# bb_top_model: IP-XACT component
VLNV IcronTechnologies:IcronTechnologies:bb_top_model:1.0

## Parameters
addr_width = 9
bus_width = 32

## Bus interfaces (logical=physical port)
default_map: slave AGNISYS:AGNISYS:APB:1.0, memory map bb_topmap
  pclk=pclk, presetn=presetn, psel=psel, penable=penable, pwrite=pwrite, pprot=pprot, pstrb=pstrb, pwdata=pwdata, paddr=paddr, pready=pready, prdata=prdata, pslverr=pslverr

## Ports
in pclk
in presetn
in psel
in penable
in pwrite
in pprot[2:0]
in pstrb[(bus_width div 8 )-1:0]
in pwdata[bus_width -1:0]
in paddr[addr_width -1:0]
out pready
out prdata[bus_width -1:0]
out pslverr
in bb_top_regssys_config_env_info_in[7:0]
in bb_top_regssys_config_env_info_in_enb
in bb_top_regssys_config_platform_support_in[7:0]
in bb_top_regssys_config_platform_support_in_enb
in bb_top_regssys_config_base_platform_in[3:0]
in bb_top_regssys_config_base_platform_in_enb
in bb_top_regssys_config_image_type_in[1:0]
in bb_top_regssys_config_image_type_in_enb
in bb_top_regssys_config_part_number_in[3:0]
in bb_top_regssys_config_part_number_in_enb
in bb_top_regssys_config_vendor_in[1:0]
in bb_top_regssys_config_vendor_in_enb
in bb_top_regssys_config_technology_in
in bb_top_regssys_config_technology_in_enb
in bb_top_regsfeature_dp_gtp_in
in bb_top_regsfeature_dp_gtp_in_enb
in bb_top_regsfeature_xadc_in
in bb_top_regsfeature_xadc_in_enb
in bb_top_regsfeature_sl_5g_in
in bb_top_regsfeature_sl_5g_in_enb
in bb_top_regsfeature_rxaui_l0_t1_in
in bb_top_regsfeature_rxaui_l0_t1_in_enb
in bb_top_regsfeature_rxaui_l0_t0_in
in bb_top_regsfeature_rxaui_l0_t0_in_enb
out bb_top_regslink_ctrl_enb
out bb_top_regslink_ctrl_sel_r
out bb_top_regsmdio_ctrl_enb
out bb_top_regsmdio_ctrl_master_bus_sel_r
out bb_top_regsmdio_ctrl_master_mdc_tri_r
out bb_top_regsi2c_ctrl_enb
out bb_top_regsi2c_ctrl_master_bus_sel_r
out bb_top_regsi2c_ctrl_master_scl_tri_r
out bb_top_regsuart_ctrl_enb
out bb_top_regsuart_ctrl_ge_uart_sel_r
out bb_top_regssfp_ctrl_enb
out bb_top_regssfp_ctrl_tx_disable_r
out bb_top_regssfp_ctrl_rs1_r
out bb_top_regssfp_ctrl_rs0_r
in bb_top_regssfp_status_rx_los_in
in bb_top_regssfp_status_rx_los_in_enb
in bb_top_regssfp_status_tx_fault_in
in bb_top_regssfp_status_tx_fault_in_enb
in bb_top_regssfp_status_mod_abs_in
in bb_top_regssfp_status_mod_abs_in_enb
out bb_top_regsusb3phy_ctrl_enb
out bb_top_regsusb3phy_ctrl_force_tx_elec_idle_r
out bb_top_regsusb3phy_ctrl_strapping_done_r
out bb_top_regsusb3phy_ctrl_xtal_dis_r
out bb_top_regsusb3phy_ctrl_ssc_dis_r
out bb_top_regsusb3phy_ctrl_power_present_r
out bb_top_regsusb3phy_ctrl_power_present_sel_r
out bb_top_regsusb3phy_ctrl_out_enable_r
out bb_top_regsusb3phy_ctrl_tx_clk_en_r
out bb_top_regsusb3phy_ctrl_rst_b_r
out bb_top_regsge_ctrl_enb
out bb_top_regsge_ctrl_int_n_r
out bb_top_regsge_ctrl_vbus_det_r
out bb_top_regsge_ctrl_clm_tx_clk_en_r
out bb_top_regsge_ctrl_ref_clk_en_r
out bb_top_regsge_ctrl_boot_sel_r
out bb_top_regsge_ctrl_rst_b_r
out bb_top_regsxmii_ctrl_enb
out bb_top_regsxmii_ctrl_txd_tri_r[7:0]
out bb_top_regsxmii_ctrl_tx_er_tri_r
out bb_top_regsxmii_ctrl_tx_en_tri_r
out bb_top_regsxmii_ctrl_gtx_clk_en_r
out bb_top_regsxmii_ctrl_rst_b_r
out bb_top_regsrs232_ctrl_enb
in bb_top_regsrs232_ctrl_invalid_b_in
in bb_top_regsrs232_ctrl_invalid_b_in_enb
out bb_top_regsrs232_ctrl_force_off_b_r
out bb_top_regsrs232_ctrl_en_b_r
out bb_top_regsicap_wdata_enb
out bb_top_regsicap_wdata_val_r[31:0]
out bb_top_regsregicap_wdata_val_wr_pulse
out bb_top_regsregicap_rdata_val_wr_pulse
out bb_top_regsgrm_soft_rst_ctrl_enb
out bb_top_regsgrm_soft_rst_ctrl_cpu_rst_r
out bb_top_regsgrm_soft_rst_ctrl_link_stats_rx_rst_r
out bb_top_regsgrm_soft_rst_ctrl_sl_5g_rx_rst_r
out bb_top_regsgrm_soft_rst_ctrl_sl_5g_tx_rst_r
out bb_top_regsgrm_soft_rst_ctrl_xmii_rx_rst_r
out bb_top_regsgrm_soft_rst_ctrl_xmii_tx_rst_r
out bb_top_regsgrm_soft_rst_ctrl_ge_clm_rx_rst_r
out bb_top_regsgrm_soft_rst_ctrl_ge_clm_tx_rst_r
out bb_top_regsgrm_soft_rst_ctrl_rs232_rst_r
out bb_top_regsgrm_soft_rst_ctrl_ulp_phy_rst_r
out bb_top_regsgrm_soft_rst_ctrl_ulp_core_rst_r
out bb_top_regsgrm_soft_rst_ctrl_upp_rst_r
out bb_top_regsgrm_soft_rst_ctrl_xusb_rst_r
out bb_top_regsgrm_soft_rst_ctrl_tico_d_ctrl_rst_r
out bb_top_regsgrm_soft_rst_ctrl_dp_source_rst_r
out bb_top_regsgrm_soft_rst_ctrl_tico_e_ctrl_rst_r
out bb_top_regsgrm_soft_rst_ctrl_dp_sink_rst_r
out bb_top_regsgrm_soft_rst_ctrl_dp_aux_hpd_rst_r
out bb_top_regsgrm_soft_rst_ctrl_mca_core_rx_rst_r
out bb_top_regsgrm_soft_rst_ctrl_mca_core_tx_rst_r
out bb_top_regsgrm_soft_rst_ctrl_l3_rx_rst_r
out bb_top_regsgrm_soft_rst_ctrl_l3_tx_rst_r
out bb_top_regsgrm_soft_rst_ctrl_dll_rx_rst_r
out bb_top_regsgrm_soft_rst_ctrl_dll_tx_rst_r
out bb_top_regsgrm_soft_rst_ctrl_gpio_ctrl_rst_r
out bb_top_regsgrm_soft_rst_ctrl_spi_flash_ctrl_rst_r
out bb_top_regsgrm_soft_rst_ctrl_mdio_master_rst_r
out bb_top_regsgrm_soft_rst_ctrl_i2c_slave_rst_r
out bb_top_regsgrm_soft_rst_ctrl_i2c_master_rst_r
out bb_top_regsgrm_soft_rst_ctrl_ge_uart_rst_r
out bb_top_regsgrm_soft_rst_ctrl_bb_uart_rst_r
out bb_top_regsgcm_control_enb
out bb_top_regsgcm_control_link_gt_common_pll0reset_r
out bb_top_regsgcm_control_xmii_tx_clk_sel_r
out bb_top_regsgcm_control_ulp_phy_clk_pll_rst_r
out bb_top_regsgcm_freq_det_enb
out bb_top_regsgcm_freq_det_max_count_r[7:0]
out bb_top_regsgcm_freq_det_clk_sel_r[2:0]
out bb_top_regsgcm_freq_det_go_r
out bb_top_regsgcm_freq_det_dp_enb
out bb_top_regsgcm_freq_det_dp_max_count_r[13:0]
out bb_top_regsgcm_freq_det_dp_clk_sel_r
out bb_top_regsgcm_freq_det_dp_go_r
out bb_top_regsgcm_freq_det_dp_auto_enb
out bb_top_regsgcm_freq_det_dp_auto_auto_enable_r
out bb_top_regsgcm_freq_det_dp_auto_comp_ref_clk_faster_r
out bb_top_regsgcm_freq_det_dp_auto_comp_count_max_r[13:0]
out bb_top_regsgcm_freq_det_dp_auto_comp_count_min_r[13:0]
out bb_top_regsdrp_drp_ctrl_enb
out bb_top_regsdrp_drp_ctrl_drp_di_r[15:0]
out bb_top_regsdrp_drp_ctrl_drp_we_r
out bb_top_regsdrp_drp_ctrl_drp_addr_r[8:0]
out bb_top_regsdrp_drp_en_mask_enb
out bb_top_regsdrp_drp_en_mask_xadc_r
out bb_top_regsdrp_drp_en_mask_sl_5g_gt0_r
out bb_top_regsdrp_drp_en_mask_rxaui_gt1_r
out bb_top_regsdrp_drp_en_mask_rxaui_gt0_r
out bb_top_regsdrp_drp_en_mask_link_mmcm_r
out bb_top_regsdrp_drp_en_mask_link_gt_common_r
out bb_top_regsdrp_drp_en_mask_dp_gt_rxoutclk_mmcm_r
out bb_top_regsdrp_drp_en_mask_dp_gt_txoutclk_mmcm_r
out bb_top_regsdrp_drp_en_mask_dp_gt_common_r
out bb_top_regsdrp_drp_en_mask_dp_gt{n}_r (n=0..3)
out bb_top_regsregdrp_drp_en_mask_dp_gt0_wr_pulse
out bb_top_regsdp_gtp_common_pll_ctrl_enb
out bb_top_regsdp_gtp_common_pll_ctrl_pll1refclksel_r[2:0]
out bb_top_regsdp_gtp_common_pll_ctrl_pll0refclksel_r[2:0]
out bb_top_regsdp_gtp_common_pll_ctrl_pll1pd_r
out bb_top_regsdp_gtp_common_pll_ctrl_pll0pd_r
out bb_top_regsdp_gtp_common_loopback_ctrl_enb
out bb_top_regsdp_gtp_common_loopback_ctrl_gt{n}_loopback_r[2:0] (n=0..3)
out bb_top_regsdp_gtp_tx_tx_clk_ctrl_enb
out bb_top_regsdp_gtp_tx_tx_clk_ctrl_gt{n}_txsysclksel_r[1:0] (n=0..3)
out bb_top_regsdp_gtp_tx_tx_rst_ctrl_enb
out bb_top_regsdp_gtp_tx_tx_rst_ctrl_gt{n}_txpcsreset_r (n=0..3)
out bb_top_regsdp_gtp_tx_tx_rst_ctrl_soft_reset_tx_r
out bb_top_regsdp_gtp_tx_tx_diff_ctrl_enb
out bb_top_regsdp_gtp_tx_tx_diff_ctrl_gt{n}_txdiffctrl_r[3:0] (n=0..3)
out bb_top_regsdp_gtp_tx_tx_post_cursor_enb
out bb_top_regsdp_gtp_tx_tx_post_cursor_gt{n}_txpostcursor_r[4:0] (n=0..3)
out bb_top_regsdp_gtp_tx_tx_pre_cursor_enb
out bb_top_regsdp_gtp_tx_tx_pre_cursor_gt{n}_txprecursor_r[4:0] (n=0..3)
out bb_top_regsdp_gtp_tx_tx_prbs_ctrl_enb
out bb_top_regsdp_gtp_tx_tx_prbs_ctrl_gt{n}_txprbsforceerr_r (n=0..3)
out bb_top_regsdp_gtp_tx_tx_prbs_ctrl_gt{n}_txprbssel_r[2:0] (n=0..3)
out bb_top_regsdp_gtp_tx_tx_misc_ctrl_enb
out bb_top_regsdp_gtp_tx_tx_misc_ctrl_gt{n}_txinhibit_r (n=0..3)
out bb_top_regsdp_gtp_tx_tx_misc_ctrl_gt{n}_txpd_r[1:0] (n=0..3)
out bb_top_regsdp_gtp_tx_tx_misc_ctrl_gt{n}_tx8b10ben_r (n=0..3)
out bb_top_regsdp_gtp_tx_tx_misc_ctrl_gt{n}_txpolarity_r (n=0..3)
out bb_top_regsdp_gtp_rx_rx_clk_ctrl_enb
out bb_top_regsdp_gtp_rx_rx_clk_ctrl_gt{n}_rxsysclksel_r[1:0] (n=0..3)
out bb_top_regsdp_gtp_rx_rx_rst_ctrl_enb
out bb_top_regsdp_gtp_rx_rx_rst_ctrl_gt{n}_rxlpmreset_r (n=0..3)
out bb_top_regsdp_gtp_rx_rx_rst_ctrl_gt{n}_eyescanreset_r (n=0..3)
out bb_top_regsdp_gtp_rx_rx_rst_ctrl_gt{n}_rxpmareset_r (n=0..3)
out bb_top_regsdp_gtp_rx_rx_rst_ctrl_gt{n}_rxpcsreset_r (n=0..3)
out bb_top_regsdp_gtp_rx_rx_rst_ctrl_dont_reset_on_data_error_r
out bb_top_regsdp_gtp_rx_rx_rst_ctrl_soft_reset_rx_r
out bb_top_regsdp_gtp_rx_rx_byte_align_ctrl_enb
out bb_top_regsdp_gtp_rx_rx_byte_align_ctrl_gt{n}_rxpcommaalignen_r (n=0..3)
out bb_top_regsdp_gtp_rx_rx_byte_align_ctrl_gt{n}_rxmcommaalignen_r (n=0..3)
out bb_top_regsdp_gtp_rx_rx_prbs_ctrl_enb
out bb_top_regsdp_gtp_rx_rx_prbs_ctrl_gt{n}_rxprbscntreset_r (n=0..3)
out bb_top_regsdp_gtp_rx_rx_prbs_ctrl_gt{n}_rxprbssel_r[2:0] (n=0..3)
out bb_top_regsdp_gtp_rx_rx_eq_ctrl_enb
out bb_top_regsdp_gtp_rx_rx_eq_ctrl_gt{n}_rxlpmlfhold_r (n=0..3)
out bb_top_regsdp_gtp_rx_rx_eq_ctrl_gt{n}_rxlpmhfovrden_r (n=0..3)
out bb_top_regsdp_gtp_rx_rx_eq_ctrl_gt{n}_rxlpmhfhold_r (n=0..3)
out bb_top_regsdp_gtp_rx_rx_misc_ctrl_enb
out bb_top_regsdp_gtp_rx_rx_misc_ctrl_gt_data_valid_en_r
out bb_top_regsdp_gtp_rx_rx_misc_ctrl_gt{n}_rxcdrhold_r (n=0..3)
out bb_top_regsdp_gtp_rx_rx_misc_ctrl_gt{n}_rxpd_r[1:0] (n=0..3)
out bb_top_regsdp_gtp_rx_rx_misc_ctrl_gt{n}_rxpolarity_r (n=0..3)
out bb_top_regsrxaui_control_enb
out bb_top_regsrxaui_control_fix_missing_start_r
out bb_top_regsrxaui_control_type_sel_r[1:0]
out bb_top_regsrxaui_control_reset_r
out bb_top_regsrxaui_gt_rst_ctrl_enb
out bb_top_regsrxaui_gt_rst_ctrl_gtrxreset_r
out bb_top_regsrxaui_gt_rst_ctrl_gt1_rxbufreset_r
out bb_top_regsrxaui_gt_rst_ctrl_gt0_rxbufreset_r
out bb_top_regsrxaui_gt_rst_ctrl_gt1_rxlpmreset_r
out bb_top_regsrxaui_gt_rst_ctrl_gt0_rxlpmreset_r
out bb_top_regsrxaui_gt_rst_ctrl_gt1_rxpcsreset_r
out bb_top_regsrxaui_gt_rst_ctrl_gt0_rxpcsreset_r
out bb_top_regsrxaui_gt_rst_ctrl_gt1_rxpmareset_r
out bb_top_regsrxaui_gt_rst_ctrl_gt0_rxpmareset_r
out bb_top_regsrxaui_gt_rst_ctrl_gt1_txpcsreset_r
out bb_top_regsrxaui_gt_rst_ctrl_gt0_txpcsreset_r
out bb_top_regsrxaui_gt_rst_ctrl_gt1_txpmareset_r
out bb_top_regsrxaui_gt_rst_ctrl_gt0_txpmareset_r
out bb_top_regsrxaui_gt_tx_diff_ctrl_enb
out bb_top_regsrxaui_gt_tx_diff_ctrl_gt1_txdiffctrl_r[3:0]
out bb_top_regsrxaui_gt_tx_diff_ctrl_gt0_txdiffctrl_r[3:0]
out bb_top_regsrxaui_gt_tx_post_cursor_enb
out bb_top_regsrxaui_gt_tx_post_cursor_gt1_txpostcursor_r[4:0]
out bb_top_regsrxaui_gt_tx_post_cursor_gt0_txpostcursor_r[4:0]
out bb_top_regsrxaui_gt_tx_pre_cursor_enb
out bb_top_regsrxaui_gt_tx_pre_cursor_gt1_txprecursor_r[4:0]
out bb_top_regsrxaui_gt_tx_pre_cursor_gt0_txprecursor_r[4:0]
out bb_top_regsrxaui_gt_rx_eq_ctrl_enb
out bb_top_regsrxaui_gt_rx_eq_ctrl_gt1_rxlpmlfovrden_r
out bb_top_regsrxaui_gt_rx_eq_ctrl_gt0_rxlpmlfovrden_r
out bb_top_regsrxaui_gt_rx_eq_ctrl_gt1_rxlpmlfhold_r
out bb_top_regsrxaui_gt_rx_eq_ctrl_gt0_rxlpmlfhold_r
out bb_top_regsrxaui_gt_rx_eq_ctrl_gt1_rxlpmhfovrden_r
out bb_top_regsrxaui_gt_rx_eq_ctrl_gt0_rxlpmhfovrden_r
out bb_top_regsrxaui_gt_rx_eq_ctrl_gt1_rxlpmhfhold_r
out bb_top_regsrxaui_gt_rx_eq_ctrl_gt0_rxlpmhfhold_r
out bb_top_regsrxaui_gt_prbs_ctrl_enb
out bb_top_regsrxaui_gt_prbs_ctrl_gt1_rxprbscntreset_r
out bb_top_regsrxaui_gt_prbs_ctrl_gt1_rxprbssel_r[2:0]
out bb_top_regsrxaui_gt_prbs_ctrl_gt0_rxprbscntreset_r
out bb_top_regsrxaui_gt_prbs_ctrl_gt0_rxprbssel_r[2:0]
out bb_top_regsrxaui_gt_prbs_ctrl_gt1_txprbsforceerr_r
out bb_top_regsrxaui_gt_prbs_ctrl_gt1_txprbssel_r[2:0]
out bb_top_regsrxaui_gt_prbs_ctrl_gt0_txprbsforceerr_r
out bb_top_regsrxaui_gt_prbs_ctrl_gt0_txprbssel_r[2:0]
out bb_top_regsrxaui_gt_misc_ctrl_enb
out bb_top_regsrxaui_gt_misc_ctrl_gt1_rxcdrhold_r
out bb_top_regsrxaui_gt_misc_ctrl_gt0_rxcdrhold_r
out bb_top_regsrxaui_gt_misc_ctrl_gt1_rxrate_r[2:0]
out bb_top_regsrxaui_gt_misc_ctrl_gt0_rxrate_r[2:0]
out bb_top_regsrxaui_gt_misc_ctrl_gt1_rxpolarity_r
out bb_top_regsrxaui_gt_misc_ctrl_gt0_rxpolarity_r
out bb_top_regsrxaui_gt_misc_ctrl_gt1_loopback_r[2:0]
out bb_top_regsrxaui_gt_misc_ctrl_gt0_loopback_r[2:0]
out bb_top_regsrxaui_gt_misc_ctrl_gt1_txpolarity_r
out bb_top_regsrxaui_gt_misc_ctrl_gt0_txpolarity_r
out bb_top_regsrxaui_gt_misc_ctrl_gt1_txinhibit_r
out bb_top_regsrxaui_gt_misc_ctrl_gt0_txinhibit_r
out bb_top_regsrxaui_stats0_rd2clr_config_enb
out bb_top_regsrxaui_stats0_rd2clr_config_missing_start_r
out bb_top_regsrxaui_stats0_rd2clr_config_gt1_not_in_table_r
out bb_top_regsrxaui_stats0_rd2clr_config_gt1_disp_err_r
out bb_top_regsrxaui_stats0_rd2clr_config_gt0_not_in_table_r
out bb_top_regsrxaui_stats0_rd2clr_config_gt0_disp_err_r
out bb_top_regsrxaui_stats0_gt0_disp_err_rd_valid_out
out bb_top_regsrxaui_stats0_gt0_not_in_table_rd_valid_out
out bb_top_regsrxaui_stats0_gt1_disp_err_rd_valid_out
out bb_top_regsrxaui_stats0_gt1_not_in_table_rd_valid_out
out bb_top_regsrxaui_stats0_missing_start_rd_valid_out
out bb_top_regssl_5g_gt_rst_ctrl_enb
out bb_top_regssl_5g_gt_rst_ctrl_rxbufreset_r
out bb_top_regssl_5g_gt_rst_ctrl_rxlpmreset_r
out bb_top_regssl_5g_gt_rst_ctrl_eyescanreset_r
out bb_top_regssl_5g_gt_rst_ctrl_rxpmareset_r
out bb_top_regssl_5g_gt_rst_ctrl_rxpcsreset_r
out bb_top_regssl_5g_gt_rst_ctrl_dont_reset_on_data_error_r
out bb_top_regssl_5g_gt_rst_ctrl_soft_reset_rx_r
out bb_top_regssl_5g_gt_rst_ctrl_txpmareset_r
out bb_top_regssl_5g_gt_rst_ctrl_txpcsreset_r
out bb_top_regssl_5g_gt_rst_ctrl_soft_reset_tx_r
out bb_top_regssl_5g_gt_tx_ctrl_enb
out bb_top_regssl_5g_gt_tx_ctrl_txprbsforceerr_r
out bb_top_regssl_5g_gt_tx_ctrl_txprbssel_r[2:0]
out bb_top_regssl_5g_gt_tx_ctrl_txpostcursor_r[4:0]
out bb_top_regssl_5g_gt_tx_ctrl_txprecursor_r[4:0]
out bb_top_regssl_5g_gt_tx_ctrl_txdiffctrl_r[3:0]
out bb_top_regssl_5g_gt_tx_ctrl_txinhibit_r
out bb_top_regssl_5g_gt_tx_ctrl_txpolarity_r
out bb_top_regssl_5g_gt_tx_ctrl_txpd_r[1:0]
out bb_top_regssl_5g_gt_rx_ctrl_enb
out bb_top_regssl_5g_gt_rx_ctrl_rxprbscntreset_r
out bb_top_regssl_5g_gt_rx_ctrl_rxprbssel_r[2:0]
out bb_top_regssl_5g_gt_rx_ctrl_rxlpmlfhold_r
out bb_top_regssl_5g_gt_rx_ctrl_rxlpmhfovrden_r
out bb_top_regssl_5g_gt_rx_ctrl_rxlpmhfhold_r
out bb_top_regssl_5g_gt_rx_ctrl_rxcdrhold_r
out bb_top_regssl_5g_gt_rx_ctrl_data_valid_en_r
out bb_top_regssl_5g_gt_rx_ctrl_rxpolarity_r
out bb_top_regssl_5g_gt_rx_ctrl_rxpd_r[1:0]
out bb_top_regssl_5g_gt_misc_ctrl_enb
out bb_top_regssl_5g_gt_misc_ctrl_loopback_r[2:0]
out bb_top_regssl_5g_stats0_rd2clr_config_enb
out bb_top_regssl_5g_stats0_rd2clr_config_gt_rxbyterealign_r
out bb_top_regssl_5g_stats0_rd2clr_config_gt_not_in_table_r
out bb_top_regssl_5g_stats0_rd2clr_config_gt_disp_err_r
out bb_top_regssl_5g_stats0_gt_disp_err_rd_valid_out
out bb_top_regssl_5g_stats0_gt_not_in_table_rd_valid_out
out bb_top_regssl_5g_stats0_gt_rxbyterealign_rd_valid_out

## Address spaces and blocks
bb_topmap.bb_top: base 0x000, range 0x200, width 32

## Registers
Registers are 32-bit, read-write, reset 0x0 unless marked. A register's access mark holds for its fields unless they carry their own. Offsets are from the block's base; lines under a group give offsets from that group; [hi:lo] are bit positions; {n}, {i} and the like mark numbered series; 'fields as' and 'values as' point back to an identical list; <NAME> marks a mode.

## bb_topmap.bb_top — BlackBird Global Registers for A7 Core
Base 0x00000000
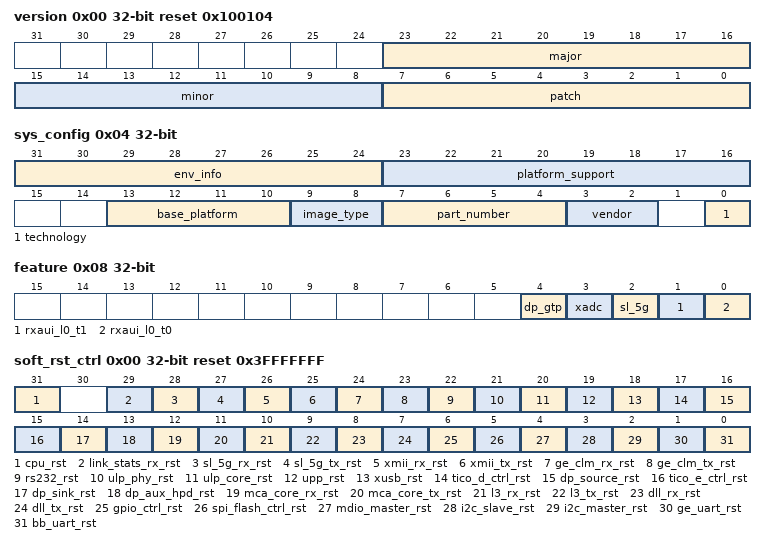
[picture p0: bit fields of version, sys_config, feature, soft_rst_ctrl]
0x00 version ro reset 0x100104
  [23:16] major — Major version
  [15:8] minor — Minor version
  [7:0] patch — Patch version
0x04 sys_config ro — System configuration
  [31:24] env_info — Environment Information - See tech register spreadsheet for details
  [23:16] platform_support — FPGA Platform Support - See tech register spreadsheet for details
  [13:10] base_platform — FPGA Base Platform - See tech register spreadsheet for details
  [9:8] image_type — FPGA Image Type - See tech register spreadsheet for details
  [7:4] part_number — Part Number - See tech register spreadsheet for details
  [3:2] vendor — Vendor Information - See tech register spreadsheet for details
  [0] technology — Technology - See tech register spreadsheet for details
0x08 feature ro — Features present
  [4] dp_gtp — DisplayPort transceivers present
  [3] xadc — XADC present
  [2] sl_5g — Single Lane 5G present
  [1] rxaui_l0_t1 — RXAUI with lane 0 mapped to transceiver 1 present
  [0] rxaui_l0_t0 — RXAUI with lane 0 mapped to transceiver 0 present
0x0C icap group — ICAP register group
  0x00 wdata — Write Data
    [31:0] val — ICAP Write Data
  0x04 rdata — Read Data
    [31:0] val — ICAP Read Data
0x14 grm group — Global Register Module registers group
  0x00 soft_rst_ctrl reset 0x3FFFFFFF — Soft Module Reset Control register
    [31] cpu_rst — CPU Reset (Active-High)
    [29] link_stats_rx_rst — Link Stats RX Reset (Active-High)
    [28] sl_5g_rx_rst — SL 5G RX Reset (Active-High)
    [27] sl_5g_tx_rst — SL 5G TX Reset (Active-High)
    [26] xmii_rx_rst — XMII RX Reset (Active-High)
    [25] xmii_tx_rst — XMII TX Reset (Active-High)
    [24] ge_clm_rx_rst — GE CLM RX Reset (Active-High)
    [23] ge_clm_tx_rst — GE CLM TX Reset (Active-High)
    [22] rs232_rst — RS-232 Reset (Active-High)
    [21] ulp_phy_rst — ULP PHY Reset (Active-High)
    [20] ulp_core_rst — ULP Core Reset (Active-High)
    [19] upp_rst — UPP Reset (Active-High)
    [18] xusb_rst — XUSB Reset (Active-High)
    [17] tico_d_ctrl_rst — TICO Decoder Control Reset (Active-High)
    [16] dp_source_rst — DisplayPort Source Reset (Active-High)
    [15] tico_e_ctrl_rst — TICO Encoder Control Reset (Active-High)
    [14] dp_sink_rst — DisplayPort Sink Reset (Active-High)
    [13] dp_aux_hpd_rst — DisplayPort AUX and HPD Reset (Active-High)
    [12] mca_core_rx_rst — MCA Core RX Reset (Active-High)
    [11] mca_core_tx_rst — MCA Core TX Reset (Active-High)
    [10] l3_rx_rst — Layer 3 RX Reset (Active-High)
    [9] l3_tx_rst — Layer 3 TX Reset (Active-High)
    [8] dll_rx_rst — Data Link Layer RX Reset (Active-High)
    [7] dll_tx_rst — Data Link Layer TX Reset (Active-High)
    [6] gpio_ctrl_rst — GPIO Controller Reset (Active-High)
    [5] spi_flash_ctrl_rst — SPI Flash Controller Reset (Active-High)
    [4] mdio_master_rst — MDIO Master Reset (Active-High)
    [3] i2c_slave_rst — I2C Slave Reset (Active-High)
    [2] i2c_master_rst — I2C Master Reset (Active-High)
    [1] ge_uart_rst — GoldenEars UART Reset (Active-High)
    [0] bb_uart_rst — BlackBird UART Reset (Active-High)
0x18 gcm group — Global Clock Module register group
  0x00 control reset 0x101 — GCM Control register
    [8] link_gt_common_pll0reset — Link GTPE2 COMMON PLL0RESET (Active-High) (See UG482, Table 2-8)
    [4] xmii_tx_clk_sel — XMII TX CLK Select: 0 : GMII Reference Clock 1 : TX_CLK
    [0] ulp_phy_clk_pll_rst — ULP PHY Clock PLL Reset (Active-High)
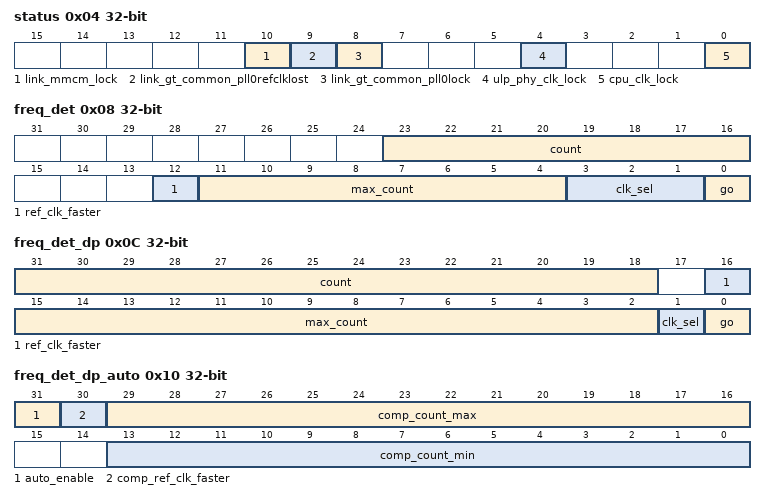
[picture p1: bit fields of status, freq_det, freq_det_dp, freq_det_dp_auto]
  0x04 status ro — GCM Status register
    [10] link_mmcm_lock — Link MMCM (Active-High)
    [9] link_gt_common_pll0refclklost — Link GTPE2 COMMON PLL0REFCLKLOST (Active-High) (See UG482, Table 2-8)
    [8] link_gt_common_pll0lock — Link GTPE2 COMMON PLL0LOCK (Active-High) (See UG482, Table 2-8)
    [4] ulp_phy_clk_lock — ULP PHY Clock PLL Lock (Active-High)
    [0] cpu_clk_lock — CPU Clock MMCM Lock (Active-High)
  0x08 freq_det access per field — Frequency Detect register
    [23:16] count ro — Count value used for frequency calculation: if (ref_clk_faster) freq_min(det_clk) = freq(ref_clk)*((count+2)/(max_count+1)) freq_max(det_clk) = freq(ref_clk)*((count+4)/(max_count-1)) else freq_min(det_clk) = freq(ref_clk)*((max_count+2)/(count+1)) freq_max(det_clk) = freq(ref_clk)*((max_count+4)/(count-1))
    [12] ref_clk_faster ro — This field determines if the reference clock (CPU Clock) is faster than the measured clock (Active-High)
    [11:4] max_count rw — This is the value used for the i_counter_max port of the freq_det module.
    [3:1] clk_sel rw — This field determines which clock is going to be measured: 0 : XMII RX Clock 1 : GE CLM RX Clock 2-7 : Reserved
    [0] go rw — Write a 1 to initiate frequency detection. HW will clear this field upon completion. Once cleared the frequency calculation can be done.
  0x0C freq_det_dp access per field — Frequency Detect DP register
    [31:18] count ro — Count value used for frequency calculation: if (ref_clk_faster) freq_min(det_clk) = freq(ref_clk)*((count+2)/(max_count+1)) freq_max(det_clk) = freq(ref_clk)*((count+4)/(max_count-1)) else freq_min(det_clk) = freq(ref_clk)*((max_count+2)/(count+1)) freq_max(det_clk) = freq(ref_clk)*((max_count+4)/(count-1))
    [16] ref_clk_faster ro — This field determines if the reference clock (CPU Clock) is faster than the measured clock (Active-High)
    [15:2] max_count rw — This is the value used for the i_counter_max port of the freq_det module.
    [1] clk_sel rw — This field determines which clock is going to be measured: 0 : DP GTREFCLK1 (TX Reference Clock) 1 : DP GTREFCLK0 (RX Recovered Clock) 2-7 : Reserved
    [0] go rw — Write a 1 to initiate frequency detection. HW will clear this field upon completion. Once cleared the frequency calculation can be done.
  0x10 freq_det_dp_auto — Frequency Detect DP Auto register
    [31] auto_enable — Automatic Mode Enable: 0 : Manual Mode 1 : Automatic Mode
    [30] comp_ref_clk_faster — In automatic mode the freq_det_dp.ref_clk_faster gets compared with this value
    [29:16] comp_count_max — In automatic mode the freq_det_dp.count gets compared with this value
    [13:0] comp_count_min — In automatic mode the freq_det_dp.count gets compared with this value
0x2C irq group — BlackBird Top Interrupt register group
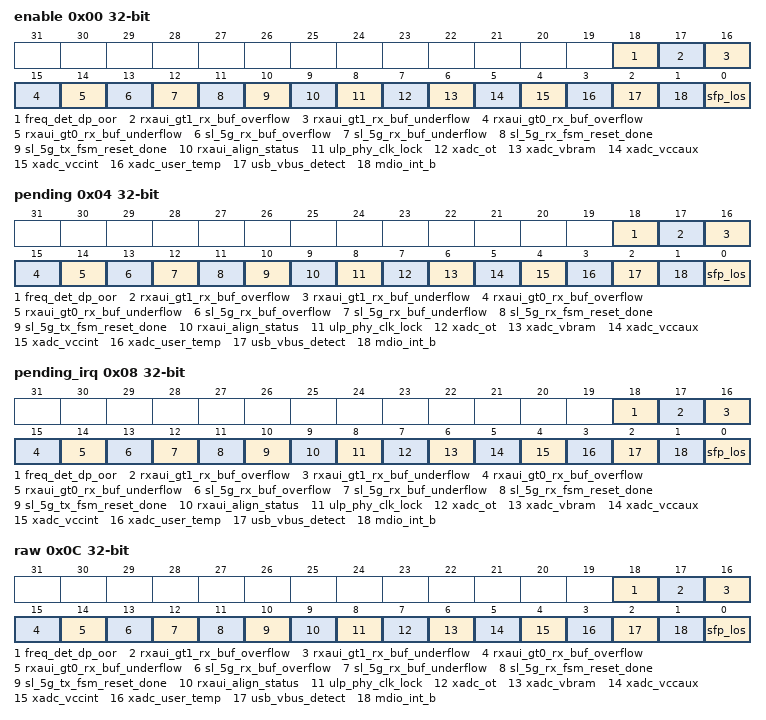
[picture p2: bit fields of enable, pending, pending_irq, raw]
  0x00 enable — Interrupt Enable register - Write 1 to enable, 0 to mask an interrupt
    [18] freq_det_dp_oor — Frequency Detect DP Out Of Range
    [17] rxaui_gt1_rx_buf_overflow — RXAUI GT1 RX Elastic Buffer Overflow (RXBUFSTATUS was 3'b110)
    [16] rxaui_gt1_rx_buf_underflow — RXAUI GT1 RX Elastic Buffer Underflow (RXBUFSTATUS was 3'b101)
    [15] rxaui_gt0_rx_buf_overflow — RXAUI GT0 RX Elastic Buffer Overflow (RXBUFSTATUS was 3'b110)
    [14] rxaui_gt0_rx_buf_underflow — RXAUI GT0 RX Elastic Buffer Underflow (RXBUFSTATUS was 3'b101)
    [13] sl_5g_rx_buf_overflow — SL 5G RX Elastic Buffer Overflow (RXBUFSTATUS was 3'b110)
    [12] sl_5g_rx_buf_underflow — SL 5G RX Elastic Buffer Underflow (RXBUFSTATUS was 3'b101)
    [11] sl_5g_rx_fsm_reset_done — SL 5G RX FSM Reset Done Interrupt
    [10] sl_5g_tx_fsm_reset_done — SL 5G TX FSM Reset Done Interrupt
    [9] rxaui_align_status — RXAUI Align Status Interrupt
    [8] ulp_phy_clk_lock — ULP PHY Clock PLL Lock Interrupt
    [7] xadc_ot — XADC Over-Temperature Alarm Interrupt
    [6] xadc_vbram — XADC VBRAM Sensor Alarm Interrupt
    [5] xadc_vccaux — XADC VCCAUX Sensor Alarm Interrupt
    [4] xadc_vccint — XADC VCCINT Sensor Alarm Interrupt
    [3] xadc_user_temp — XADC Temperature Sensor Alarm Interrupt
    [2] usb_vbus_detect — USB VBUS Detect Interrupt
    [1] mdio_int_b — MDIO Interrupt
    [0] sfp_los — SFP+ Module Connector LOS Interrupt
  0x04 pending — Pending register - This indicates which events are pending, Write 1 to clear
    [18] freq_det_dp_oor write-1-clears — Edge-triggered - Active-High Frequency Detect DP Out Of Range
    [17] rxaui_gt1_rx_buf_overflow write-1-clears — Edge-triggered - Active-High RXAUI GT1 RX Elastic Buffer Overflow
    [16] rxaui_gt1_rx_buf_underflow write-1-clears — Edge-triggered - Active-High RXAUI GT1 RX Elastic Buffer Underflow
    [15] rxaui_gt0_rx_buf_overflow write-1-clears — Edge-triggered - Active-High RXAUI GT0 RX Elastic Buffer Overflow
    [14] rxaui_gt0_rx_buf_underflow write-1-clears — Edge-triggered - Active-High RXAUI GT0 RX Elastic Buffer Underflow
    [13] sl_5g_rx_buf_overflow write-1-clears — Edge-triggered - Active-High SL 5G RX Elastic Buffer Overflow
    [12] sl_5g_rx_buf_underflow write-1-clears — Edge-triggered - Active-High SL 5G RX Elastic Buffer Underflow
    [11] sl_5g_rx_fsm_reset_done write-1-clears — Edge-triggered - Rising and Falling Edge SL 5G RX FSM Reset Done
    [10] sl_5g_tx_fsm_reset_done write-1-clears — Edge-triggered - Active-High SL 5G TX FSM Reset Done
    [9] rxaui_align_status write-1-clears — Edge-triggered - Rising and Falling Edge RXAUI Align Status
    [8] ulp_phy_clk_lock write-1-clears — Edge-triggered - Active High ULP PHY Clock PLL Lock
    [7] xadc_ot write-1-clears — Edge-triggered - Active High XADC Over-Temperature Alarm
    [6] xadc_vbram write-1-clears — Edge-triggered - Active High XADC VBRAM Sensor Alarm
    [5] xadc_vccaux write-1-clears — Edge-triggered - Active High XADC VCCAUX Sensor Alarm
    [4] xadc_vccint write-1-clears — Edge-triggered - Active High XADC VCCINT Sensor Alarm
    [3] xadc_user_temp write-1-clears — Edge-triggered - Active High XADC Temperature Sensor Alarm
    [2] usb_vbus_detect write-1-clears — Edge-triggered - Rising and Falling Edge USB VBUS Detect change
    [1] mdio_int_b write-1-clears — Level-triggered - Active-Low MDIO Interrupt
    [0] sfp_los write-1-clears — Edge-triggered - Rising and Falling Edge SFP+ Module Connector LOS change
  0x08 pending_irq ro — Interrupt Pending register - This indicates which pending events are enabled to cause an interrupt
    [18] freq_det_dp_oor — Edge-triggered - Active-High Frequency Detect DP Out Of Range
    [17] rxaui_gt1_rx_buf_overflow — Edge-triggered - Active-High RXAUI GT1 RX Elastic Buffer Overflow
    [16] rxaui_gt1_rx_buf_underflow — Edge-triggered - Active-High RXAUI GT1 RX Elastic Buffer Underflow
    [15] rxaui_gt0_rx_buf_overflow — Edge-triggered - Active-High RXAUI GT0 RX Elastic Buffer Overflow
    [14] rxaui_gt0_rx_buf_underflow — Edge-triggered - Active-High RXAUI GT0 RX Elastic Buffer Underflow
    [13] sl_5g_rx_buf_overflow — Edge-triggered - Active-High SL 5G RX Elastic Buffer Overflow
    [12] sl_5g_rx_buf_underflow — Edge-triggered - Active-High SL 5G RX Elastic Buffer Underflow
    [11] sl_5g_rx_fsm_reset_done — Edge-triggered - Rising and Falling Edge SL 5G RX FSM Reset Done
    [10] sl_5g_tx_fsm_reset_done — Edge-triggered - Active-High SL 5G TX FSM Reset Done
    [9] rxaui_align_status — Edge-triggered - Rising and Falling Edge RXAUI Align Status
    [8] ulp_phy_clk_lock — Edge-triggered - Active High ULP PHY Clock PLL Lock
    [7] xadc_ot — Edge-triggered - Active High XADC Over-Temperature Alarm
    [6] xadc_vbram — Edge-triggered - Active High XADC VBRAM Sensor Alarm
    [5] xadc_vccaux — Edge-triggered - Active High XADC VCCAUX Sensor Alarm
    [4] xadc_vccint — Edge-triggered - Active High XADC VCCINT Sensor Alarm
    [3] xadc_user_temp — Edge-triggered - Active High XADC Temperature Sensor Alarm
    [2] usb_vbus_detect — Edge-triggered - Rising and Falling Edge USB VBUS Detect change
    [1] mdio_int_b — Level-triggered - Active-Low MDIO Interrupt
    [0] sfp_los — Edge-triggered - Rising and Falling Edge SFP+ Module Connector LOS change
  0x0C raw ro — This register contains the registered state of interrupt signals
    [18] freq_det_dp_oor — Current state of the Frequency Detect DP Out Of Range (Active-High)
    [17] rxaui_gt1_rx_buf_overflow — Current state of the RXAUI GT1 RX Elastic Buffer Overflow (Active-High)
    [16] rxaui_gt1_rx_buf_underflow — Current state of the RXAUI GT1 RX Elastic Buffer Underflow (Active-High)
    [15] rxaui_gt0_rx_buf_overflow — Current state of the RXAUI GT0 RX Elastic Buffer Overflow (Active-High)
    [14] rxaui_gt0_rx_buf_underflow — Current state of the RXAUI GT0 RX Elastic Buffer Underflow (Active-High)
    [13] sl_5g_rx_buf_overflow — Current state of the SL 5G RX Elastic Buffer Overflow (Active-High)
    [12] sl_5g_rx_buf_underflow — Current state of the SL 5G RX Elastic Buffer Underflow (Active-High)
    [11] sl_5g_rx_fsm_reset_done — Current state of the SL 5G RX FSM Reset Done (Active-High)
    [10] sl_5g_tx_fsm_reset_done — Current state of the SL 5G TX FSM Reset Done (Active-High)
    [9] rxaui_align_status — Current state of the RXAUI Align Status (Active-High)
    [8] ulp_phy_clk_lock — Current state of the ULP PHY Clock PLL Lock (Active-High)
    [7] xadc_ot — Current state of the XADC Over-Temperature Alarm (Active-High)
    [6] xadc_vbram — Current state of the XADC VBRAM Sensor Alarm (Active-High)
    [5] xadc_vccaux — Current state of the XADC VCCAUX Sensor Alarm (Active-High)
    [4] xadc_vccint — Current state of the XADC VCCINT Sensor Alarm (Active-High)
    [3] xadc_user_temp — Current state of the XADC Temperature Sensor Alarm (Active-High)
    [2] usb_vbus_detect — Current state of the USB VBUS Detect (Active-High)
    [1] mdio_int_b — Current state of the MDIO Interrupt (Active-Low)
    [0] sfp_los — Current state of the SFP+ Module Connector LOS (Active-High)
0x3C link_ctrl — Link Control
  [0] sel — Link Select 0 : RXAUI 1 : SL 5G
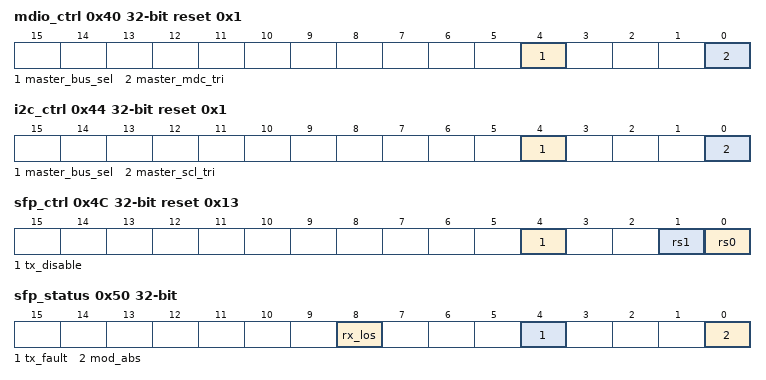
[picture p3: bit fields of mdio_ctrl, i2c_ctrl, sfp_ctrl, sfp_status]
0x40 mdio_ctrl reset 0x1 — MDIO Control
  [4] master_bus_sel — MDIO Master Bus Select 0 : Mother board (connector) 1 : RXAUI Core (internal)
  [0] master_mdc_tri — MDIO Master Clock (MDC) Tri-State (Active-High)
0x44 i2c_ctrl reset 0x1 — I2C Control
  [4] master_bus_sel — I2C Master Bus Select 0 : Core board (local) 1 : Mother board (connector)
  [0] master_scl_tri — I2C Master Clock (SCL) Tri-State (Active-High)
0x48 uart_ctrl — UART Control
  [0] ge_uart_sel — GE UART Select 0 : Mother board (connector) 1 : GE UART (internal)
0x4C sfp_ctrl reset 0x13 — SFP Control
  [4] tx_disable — Transmitter Disable 0 : Module transmitter enabled 1 : Module transmitter disabled
  [1] rs1 — Rate Select TX 0 : TX signalling rate less than or equal to 4.25 GBd 1 : TX signalling rate greater than 4.25 GBd
  [0] rs0 — Rate Select RX 0 : RX signalling rate less than or equal to 4.25 GBd 1 : RX signalling rate greater than 4.25 GBd
0x50 sfp_status ro
  [8] rx_los — RX LOS (Active-High) - Indicates an optical signal level below that specified in the relevant standard
  [4] tx_fault — TX Fault (Active-High) - Module transmitter detected a fault
  [0] mod_abs — Module Absent (Active-High) - SFP+ module is physically absent
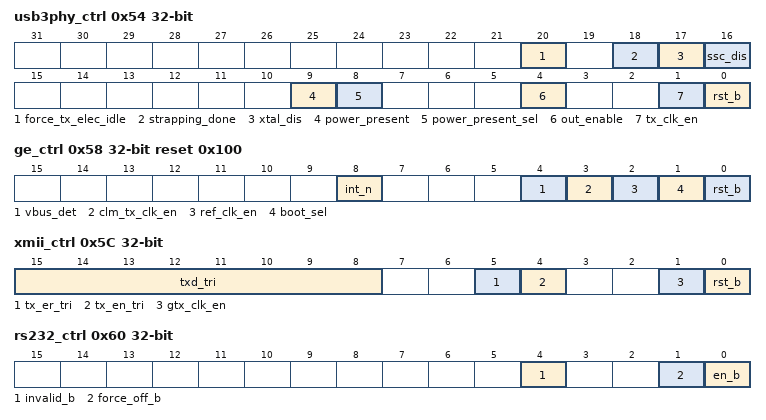
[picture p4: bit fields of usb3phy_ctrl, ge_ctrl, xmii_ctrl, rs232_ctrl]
0x54 usb3phy_ctrl — USB3PHY Control
  [20] force_tx_elec_idle — When this is set to 1, it forces the FPGA PIPE TX to Electrical Idle. Only used for hardware test to isolate the PIPE RX path from cross talk of TX path.
  [18] strapping_done — This register is used for dynamic strapping to select the proper path for strap options: xtal_dis and ssc_dis. Assert high when strapping is completed (This should be asserted after PHY is out of reset using rst_b). See also "out_enable"
  [17] xtal_dis — Strap Option - Selects an input clock source 0 : Crystal input 1 : Clock input
  [16] ssc_dis — Strap Option - Spread spectrum clocking disable 0 : SSC enable 1 : SSC disable
  [9] power_present — Power Present to the ULP
  [8] power_present_sel — Power Present Select for the ULP: 0 : VBUS Detect 1 : usb3phy_ctrl.power_present register field
  [4] out_enable — Assert high to enable PHY outputs. Assert after PHY is out of reset and when dynamic strapping is complete. See rst_b and strapping_done.
  [1] tx_clk_en — Forwarded TX Clock Enable (Active-High)
  [0] rst_b — Reset (Active-Low)
0x58 ge_ctrl reset 0x100 — GE Control
  [8] int_n — Interrupt (Active-Low)
  [4] vbus_det — VBUS Detect (Active-High)
  [3] clm_tx_clk_en — Forwarded CLM TX Clock Enable (Active-High)
  [2] ref_clk_en — 125 MHz Reference Clock Enable (Active-High)
  [1] boot_sel — Boot Select 0 : Program Mode 1 : Boot from Flash
  [0] rst_b — Reset (Active-Low)
0x5C xmii_ctrl — XMII Control
  [15:8] txd_tri — TXD Tri-State (Active-High)
  [5] tx_er_tri — TX ER Tri-State (Active-High)
  [4] tx_en_tri — TX EN Tri-State (Active-High)
  [1] gtx_clk_en — Forwarded GTX Clock Enable (Active-High)
  [0] rst_b — Reset (Active-Low)
0x60 rs232_ctrl access per field — RS232 Control
  [4] invalid_b ro — Receiver Input (RIN) Invalid (Active-Low)
  [1] force_off_b rw — Automatic Power-Down (Active-Low)
  [0] en_b rw — Receiver Output (ROUT) Enable (Active-Low)
0x100 drp group — DRP register group
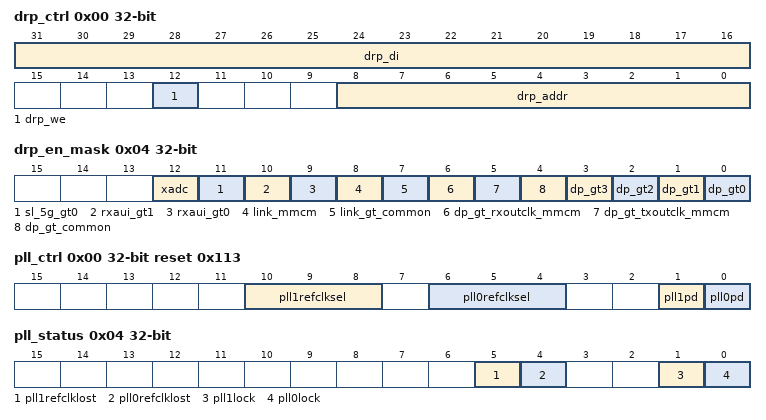
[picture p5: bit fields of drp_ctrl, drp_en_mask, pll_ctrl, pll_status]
  0x00 drp_ctrl — DRP Control and Write Data. Note: make sure this register is setup before writing to the drp_en_mask register
    [31:16] drp_di — DRP Write Data
    [12] drp_we — DRP Write Enable
    [8:0] drp_addr — DRP Address
  0x04 drp_en_mask — DRP Enable Mask for each DRP bus. - A write to this register initiates a transaction to each enabled DRP bus. - A field gets cleared when its respective DRP bus asserts DRPRDY. Note: before attempting a new transaction, make sure no DRP bus is busy (all fields should be cleared) Note: always enable exactly 1 DRP bus for read transfers, write transfers can have any combination of DRP buses enabled Note: following a read transaction make sure the DRP bus has asserted DRPRDY (its DRP Enable Mask field should be cleared) before reading the drp_read_data register.
    [12] xadc — DRP Enable Mask for XADC
    [11] sl_5g_gt0 — DRP Enable Mask for SL 5G GT0
    [10] rxaui_gt1 — DRP Enable Mask for RXAUI GT1
    [9] rxaui_gt0 — DRP Enable Mask for RXAUI GT0
    [8] link_mmcm — DRP Enable Mask for Link MMCM
    [7] link_gt_common — DRP Enable Mask for Link GT COMMON
    [6] dp_gt_rxoutclk_mmcm — DRP Enable Mask for DP GT RXOUTCLK MMCM
    [5] dp_gt_txoutclk_mmcm — DRP Enable Mask for DP GT TXOUTCLK MMCM
    [4] dp_gt_common — DRP Enable Mask for DP GT COMMON
    [n] dp_gt{n} (n=0..3) — DRP Enable Mask for DP GT{n}
  0x08 drp_read_data ro — DRP Read Data Note: make sure the DRP bus has asserted DRPRDY (its DRP Enable Mask field in the drp_en_mask register should be cleared) before reading this register
    [15:0] drp_do — DRP Read Data
0x10C dp_gtp_common group — DisplayPort GTP common register group
  0x00 pll_ctrl reset 0x113 — PLL Control
    [10:8] pll1refclksel — PLL1REFCLKSEL (See UG482, Table 2-8)
    [6:4] pll0refclksel — PLL0REFCLKSEL (See UG482, Table 2-8)
    [1] pll1pd — PLL1PD (Active-High) (See UG482, Table 2-8)
    [0] pll0pd — PLL0PD (Active-High) (See UG482, Table 2-8)
  0x04 pll_status ro
    [5] pll1refclklost — PLL1REFCLKLOST (Active-High) (See UG482, Table 2-8)
    [4] pll0refclklost — PLL0REFCLKLOST (Active-High) (See UG482, Table 2-8)
    [1] pll1lock — PLL1LOCK (Active-High) (See UG482, Table 2-8)
    [0] pll0lock — PLL0LOCK (Active-High) (See UG482, Table 2-8)
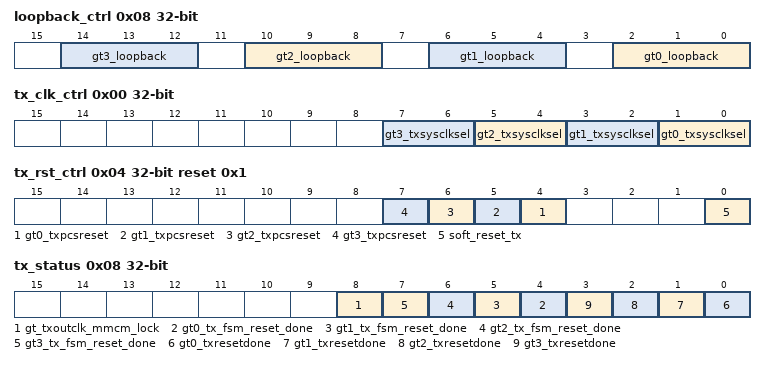
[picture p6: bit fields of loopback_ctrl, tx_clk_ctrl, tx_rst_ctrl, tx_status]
  0x08 loopback_ctrl — Loopback Control
    [4n+2:4n] gt{n}_loopback (n=0..3) — GT{n} LOOPBACK (See UG482, Table 2-27)
0x118 dp_gtp_tx group — DisplayPort GTP TX register group
  0x00 tx_clk_ctrl — GTP TX Clock Control
    [2n+1:2n] gt{n}_txsysclksel (n=0..3) — GT{n} TXSYSCLKSEL (See UG482, Table 2-6)
  0x04 tx_rst_ctrl reset 0x1 — GTP TX Reset Control
    [n+4] gt{n}_txpcsreset (n=0..3) — GT{n} TXPCSRESET (Active-High) (See UG482, Table 2-14)
    [0] soft_reset_tx — Soft Reset of TX path of all DP GTPs (Active-High) 1'b0 - All GTP TX Reset FSMs are out of reset 1'b1 - All GTP TX Reset FSMs are in reset Note: To reset write a 1 followed by a 0
  0x08 tx_status ro — GTP TX Status
    [8] gt_txoutclk_mmcm_lock — GT TXOUTCLK MMCM Lock (Active-High)
    [n+4] gt{n}_tx_fsm_reset_done (n=0..3) — GT{n} TX FSM Reset Done (Active-High)
    [n] gt{n}_txresetdone (n=0..3) — GT{n} TXRESETDONE (Active-High) (See UG482, Table 2-14)
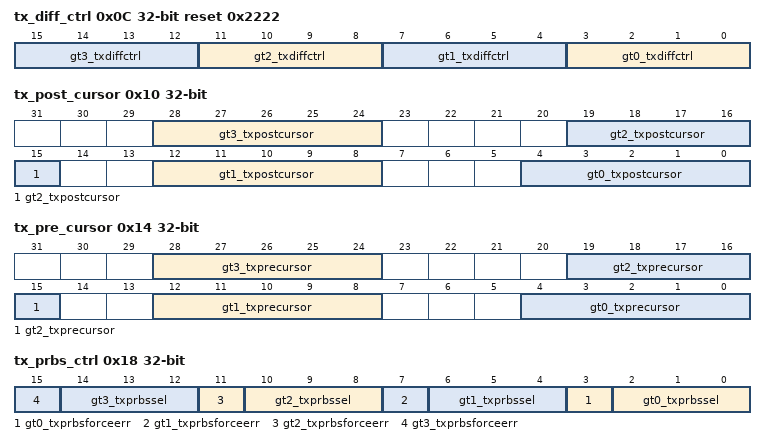
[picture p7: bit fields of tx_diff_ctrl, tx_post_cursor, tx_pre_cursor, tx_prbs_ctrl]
  0x0C tx_diff_ctrl reset 0x2222 — GTP TX Voltage Swing
    [4n+3:4n] gt{n}_txdiffctrl (n=0..3) — GT{n} TXDIFFCTRL (See UG482, Table 3-28)
  0x10 tx_post_cursor — GTP TX Pre-emphasis (Post-Cursor1)
    [28:24] gt3_txpostcursor — GT3 TXPOSTCURSOR (See UG482, Table 3-28)
    [19:15] gt2_txpostcursor — GT2 TXPOSTCURSOR (See UG482, Table 3-28)
    [12:8] gt1_txpostcursor — GT1 TXPOSTCURSOR (See UG482, Table 3-28)
    [4:0] gt0_txpostcursor — GT0 TXPOSTCURSOR (See UG482, Table 3-28)
  0x14 tx_pre_cursor — GTP TX Pre-emphasis (Pre-Cursor)
    [28:24] gt3_txprecursor — GT3 TXPRECURSOR (See UG482, Table 3-28)
    [19:15] gt2_txprecursor — GT2 TXPRECURSOR (See UG482, Table 3-28)
    [12:8] gt1_txprecursor — GT1 TXPRECURSOR (See UG482, Table 3-28)
    [4:0] gt0_txprecursor — GT0 TXPRECURSOR (See UG482, Table 3-28)
  0x18 tx_prbs_ctrl — GTP TX Pattern Generator Control
    [4n+3] gt{n}_txprbsforceerr (n=0..3) — GT{n} TXPRBSFORCEERR (Active-High) (See UG482, Table 3-20)
    [4n+2:4n] gt{n}_txprbssel (n=0..3) — GT{n} TXPRBSSEL (See UG482, Table 3-20)
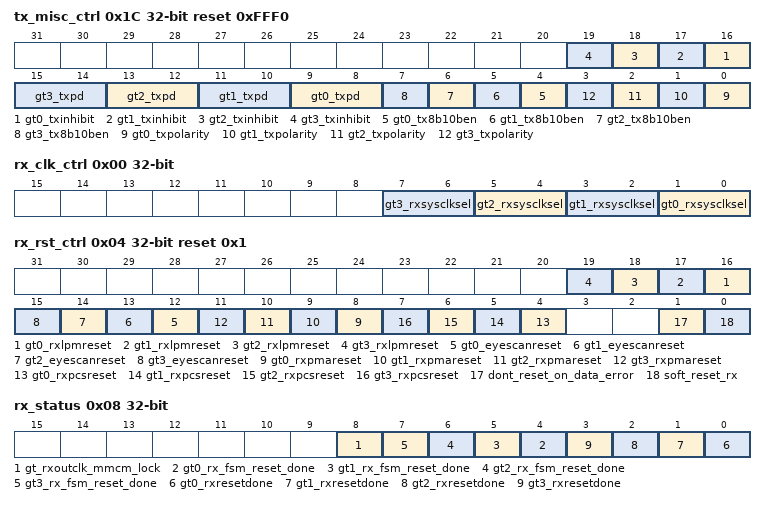
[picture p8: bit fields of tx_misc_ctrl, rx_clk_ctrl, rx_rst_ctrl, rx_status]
  0x1C tx_misc_ctrl reset 0xFFF0 — GTP TX Miscellaneous Control
    [n+16] gt{n}_txinhibit (n=0..3) — GT{n} TXINHIBIT (Active-High) (See UG482, Table 3-28)
    [2n+9:2n+8] gt{n}_txpd (n=0..3) — GT{n} TXPD (See UG482, Table 3-30)
    [n+4] gt{n}_tx8b10ben (n=0..3) — GT{n} TX8B10BEN (Active-High) (See UG482, Table 3-7)
    [n] gt{n}_txpolarity (n=0..3) — GT{n} TXPOLARITY (See UG482, Table 3-22)
0x138 dp_gtp_rx group — DisplayPort GTP RX register group
  0x00 rx_clk_ctrl — GTP TX Clock Control
    [2n+1:2n] gt{n}_rxsysclksel (n=0..3) — GT{n} RXSYSCLKSEL (See UG482, Table 2-6)
  0x04 rx_rst_ctrl reset 0x1 — GTP RX Reset Control
    [n+16] gt{n}_rxlpmreset (n=0..3) — GT{n} RXLPMRESET (Active-High) (See UG482, Table 4-18)
    [n+12] gt{n}_eyescanreset (n=0..3) — GT{n} EYESCANRESET (Active-High) (See UG482, Table 2-18)
    [n+8] gt{n}_rxpmareset (n=0..3) — GT{n} RXPMARESET (Active-High) (See UG482, Table 2-18)
    [n+4] gt{n}_rxpcsreset (n=0..3) — GT{n} RXPCSRESET (Active-High) (See UG482, Table 2-18)
    [1] dont_reset_on_data_error — Do not automatically reset the RX_STARTUP_FSM of a GTP when its DATA_VALID input de-asserts.
    [0] soft_reset_rx — Soft Reset of RX path of all DP GTPs (Active-High) 1'b0 - All GTP RX Reset FSMs are out of reset 1'b1 - All GTP RX Reset FSMs are in reset Note: To reset write a 1 followed by a 0
  0x08 rx_status ro — GTP RX Status
    [8] gt_rxoutclk_mmcm_lock — GT RXOUTCLK MMCM Lock (Active-High)
    [n+4] gt{n}_rx_fsm_reset_done (n=0..3) — GT{n} RX FSM Reset Done (Active-High)
    [n] gt{n}_rxresetdone (n=0..3) — GT{n} RXRESETDONE (Active-High) (See UG482, Table 2-18)
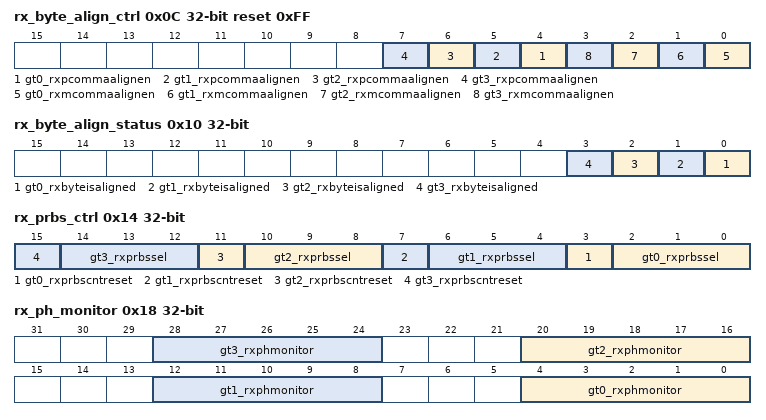
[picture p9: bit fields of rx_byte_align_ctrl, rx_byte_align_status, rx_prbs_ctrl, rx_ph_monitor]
  0x0C rx_byte_align_ctrl reset 0xFF — GTP RX Byte Alignment Control
    [n+4] gt{n}_rxpcommaalignen (n=0..3) — GT{n} RXPCOMMAALIGNEN (See UG482, Table 4-25)
    [n] gt{n}_rxmcommaalignen (n=0..3) — GT{n} RXMCOMMAALIGNEN (See UG482, Table 4-25)
  0x10 rx_byte_align_status ro — GTP RX Byte Alignment Status
    [n] gt{n}_rxbyteisaligned (n=0..3) — GT{n} RXBYTEISALIGNED (See UG482, Table 4-25)
  0x14 rx_prbs_ctrl — GTP RX Pattern Receiver Control
    [4n+3] gt{n}_rxprbscntreset (n=0..3) — GT{n} RXPRBSCNTRESET (Active-High) (See UG482, Table 4-23)
    [4n+2:4n] gt{n}_rxprbssel (n=0..3) — GT{n} RXPRBSSEL (See UG482, Table 4-23)
  0x18 rx_ph_monitor ro — GTP RX Phase Alignment Monitor
    [8n+4:8n] gt{n}_rxphmonitor (n=0..3) — GT{n} RXPHMONITOR (See UG482, Table 4-29)
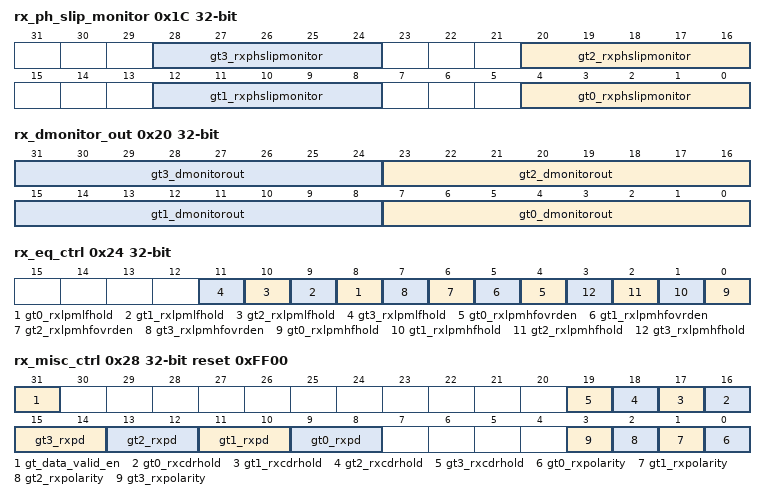
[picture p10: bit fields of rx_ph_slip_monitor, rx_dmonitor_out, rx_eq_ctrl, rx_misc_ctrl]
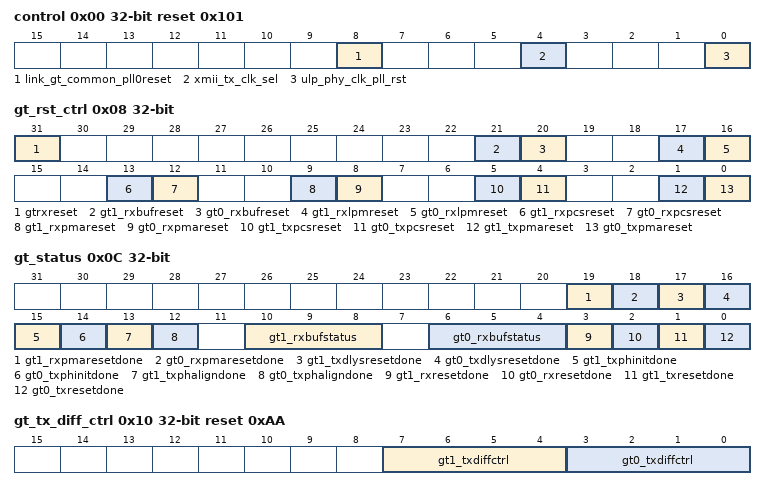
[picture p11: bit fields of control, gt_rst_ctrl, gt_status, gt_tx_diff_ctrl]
  0x1C rx_ph_slip_monitor ro — GTP RX Phase Alignment Slip Monitor
    [8n+4:8n] gt{n}_rxphslipmonitor (n=0..3) — GT{n} RXPHSLIPMONITOR (See UG482, Table 4-29)
  0x20 rx_dmonitor_out ro — GTP RX Digital Monitor Out
    [8n+7:8n] gt{n}_dmonitorout (n=0..3) — GT{n} DMONITOROUT[7:0] (See UG482, Table 2-31)
  0x24 rx_eq_ctrl — GTP RX Equalizer Control
    [n+8] gt{n}_rxlpmlfhold (n=0..3) — GT{n} RXLPMLFHOLD (See UG482, Table 4-9)
    [n+4] gt{n}_rxlpmhfovrden (n=0..3) — GT{n} RXLPMHFOVRDEN (See UG482, Table 4-9)
    [n] gt{n}_rxlpmhfhold (n=0..3) — GT{n} RXLPMHFHOLD (See UG482, Table 4-9)
  0x28 rx_misc_ctrl reset 0xFF00 — GTP RX Miscellaneous Control
    [31] gt_data_valid_en — DATA_VALID input to the GT RX_STARTUP_FSM is: 1'b0 : always 1 1'b1 : hardware defined (generally the NOT of the OR of all 8B/10B decode errors)
    [n+16] gt{n}_rxcdrhold (n=0..3) — GT{n} RXCDRHOLD (See UG482, Table 4-11)
    [2n+9:2n+8] gt{n}_rxpd (n=0..3) — GT{n} RXPD (See UG482, Table 3-30)
    [n] gt{n}_rxpolarity (n=0..3) — GT{n} RXPOLARITY (See UG482, Table 4-22)
0x164 rxaui group — RXAUI register group
  0x00 control reset 0x1
    [8] fix_missing_start — Replace the XGMII Idle with an XGMII Start control character when it is detected missing (see stats0.missing_start)
    [5:4] type_sel — Type Select (See PG083, Table 3-3)
    [0] reset — Asynchronous reset (Active-High)
  0x04 status ro
    [5:0] debug — Debug Port (See PG083, Table 2-18) [0] : TX Phase Align Complete [4:1] : Sync Status [5]: Align Status
  0x08 gt_rst_ctrl — GTP Reset Control register
    [31] gtrxreset — GT0 and GT1 GTRXRESET (Active-High) (See UG482, Table 2-18)
    [21] gt1_rxbufreset — GT1 RXBUFRESET (Active-High) (See UG482, Table 2-18)
    [20] gt0_rxbufreset — GT0 RXBUFRESET (Active-High) (See UG482, Table 2-18)
    [17] gt1_rxlpmreset — GT1 RXLPMRESET (Active-High) (See UG482, Table 2-18)
    [16] gt0_rxlpmreset — GT0 RXLPMRESET (Active-High) (See UG482, Table 2-18)
    [13] gt1_rxpcsreset — GT1 RXPCSRESET (Active-High) (See UG482, Table 2-18)
    [12] gt0_rxpcsreset — GT0 RXPCSRESET (Active-High) (See UG482, Table 2-18)
    [9] gt1_rxpmareset — GT1 RXPMARESET (Active-High) (See UG482, Table 2-18)
    [8] gt0_rxpmareset — GT0 RXPMARESET (Active-High) (See UG482, Table 2-18)
    [5] gt1_txpcsreset — GT1 TXPCSRESET (Active-High) (See UG482, Table 2-14)
    [4] gt0_txpcsreset — GT0 TXPCSRESET (Active-High) (See UG482, Table 2-14)
    [1] gt1_txpmareset — GT1 TXPMARESET (Active-High) (See UG482, Table 2-14)
    [0] gt0_txpmareset — GT0 TXPMARESET (Active-High) (See UG482, Table 2-14)
  0x0C gt_status ro — GTP Status register
    [19] gt1_rxpmaresetdone — GT1 RXPMARESETDONE (Active-High) (See UG482, Table 2-18)
    [18] gt0_rxpmaresetdone — GT0 RXPMARESETDONE (Active-High) (See UG482, Table 2-18)
    [17] gt1_txdlysresetdone — GT1 TXDLYSRESETDONE (Active-High) (See UG482, Table 3-15)
    [16] gt0_txdlysresetdone — GT0 TXDLYSRESETDONE (Active-High) (See UG482, Table 3-15)
    [15] gt1_txphinitdone — GT1 TXPHINITDONE (Active-High) (See UG482, Table 3-15)
    [14] gt0_txphinitdone — GT0 TXPHINITDONE (Active-High) (See UG482, Table 3-15)
    [13] gt1_txphaligndone — GT1 TXPHALIGNDONE (Active-High) (See UG482, Table 3-15)
    [12] gt0_txphaligndone — GT0 TXPHALIGNDONE (Active-High) (See UG482, Table 3-15)
    [10:8] gt1_rxbufstatus — GT1 RXBUFSTATUS (See UG482, Table 4-33)
    [6:4] gt0_rxbufstatus — GT0 RXBUFSTATUS (See UG482, Table 4-33)
    [3] gt1_rxresetdone — GT1 RXRESETDONE (Active-High) (See UG482, Table 2-18)
    [2] gt0_rxresetdone — GT0 RXRESETDONE (Active-High) (See UG482, Table 2-18)
    [1] gt1_txresetdone — GT1 TXRESETDONE (Active-High) (See UG482, Table 2-14)
    [0] gt0_txresetdone — GT0 TXRESETDONE (Active-High) (See UG482, Table 2-14)
  0x10 gt_tx_diff_ctrl reset 0xAA — GTP TX Voltage Swing
    [7:4] gt1_txdiffctrl — GT1 TXDIFFCTRL (See UG482, Table 3-28)
    [3:0] gt0_txdiffctrl — GT0 TXDIFFCTRL (See UG482, Table 3-28)
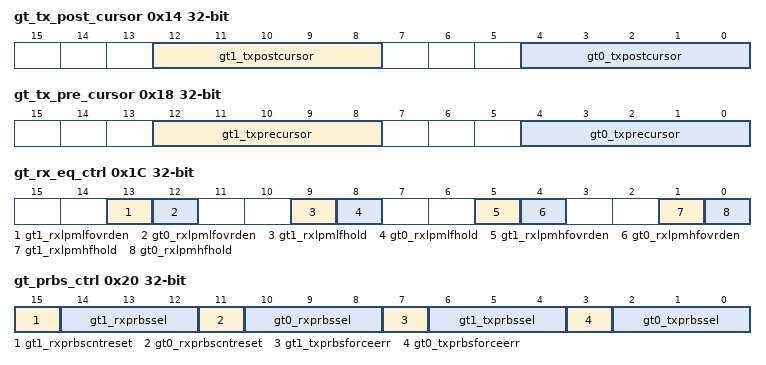
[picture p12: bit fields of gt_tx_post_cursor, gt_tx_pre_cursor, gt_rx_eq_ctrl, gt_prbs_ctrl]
  0x14 gt_tx_post_cursor — GTP TX Pre-emphasis (Post-Cursor)
    [12:8] gt1_txpostcursor — GT1 TXPOSTCURSOR (See UG482, Table 3-28)
    [4:0] gt0_txpostcursor — GT0 TXPOSTCURSOR (See UG482, Table 3-28)
  0x18 gt_tx_pre_cursor — GTP TX Pre-emphasis (Pre-Cursor)
    [12:8] gt1_txprecursor — GT1 TXPRECURSOR (See UG482, Table 3-28)
    [4:0] gt0_txprecursor — GT0 TXPRECURSOR (See UG482, Table 3-28)
  0x1C gt_rx_eq_ctrl — GTP RX Equalizer Control
    [13] gt1_rxlpmlfovrden — GT1 RXLPMLFOVRDEN (See UG482, Table 4-9)
    [12] gt0_rxlpmlfovrden — GT0 RXLPMLFOVRDEN (See UG482, Table 4-9)
    [9] gt1_rxlpmlfhold — GT1 RXLPMLFHOLD (See UG482, Table 4-9)
    [8] gt0_rxlpmlfhold — GT0 RXLPMLFHOLD (See UG482, Table 4-9)
    [5] gt1_rxlpmhfovrden — GT1 RXLPMHFOVRDEN (See UG482, Table 4-9)
    [4] gt0_rxlpmhfovrden — GT0 RXLPMHFOVRDEN (See UG482, Table 4-9)
    [1] gt1_rxlpmhfhold — GT1 RXLPMHFHOLD (See UG482, Table 4-9)
    [0] gt0_rxlpmhfhold — GT0 RXLPMHFHOLD (See UG482, Table 4-9)
  0x20 gt_prbs_ctrl — GTP Pattern Generator/Receiver Control
    [15] gt1_rxprbscntreset — GT1 RXPRBSCNTRESET (Active-High) (See UG482, Table 4-23)
    [14:12] gt1_rxprbssel — GT1 RXPRBSSEL (See UG482, Table 4-23)
    [11] gt0_rxprbscntreset — GT0 RXPRBSCNTRESET (Active-High) (See UG482, Table 4-23)
    [10:8] gt0_rxprbssel — GT0 RXPRBSSEL (See UG482, Table 4-23)
    [7] gt1_txprbsforceerr — GT1 TXPRBSFORCEERR (See UG482, Table 3-20)
    [6:4] gt1_txprbssel — GT1 TXPRBSSEL (See UG482, Table 3-20)
    [3] gt0_txprbsforceerr — GT0 TXPRBSFORCEERR (See UG482, Table 3-20)
    [2:0] gt0_txprbssel — GT0 TXPRBSSEL (See UG482, Table 3-20)
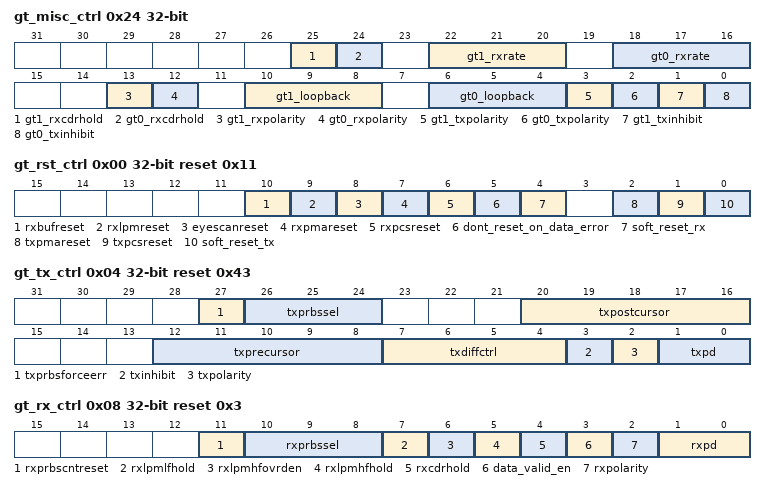
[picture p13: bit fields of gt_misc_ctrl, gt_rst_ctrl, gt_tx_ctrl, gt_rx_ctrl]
  0x24 gt_misc_ctrl — GTP Miscellaneous Control
    [25] gt1_rxcdrhold — GT1 RXCDRHOLD (See UG482, Table 4-11)
    [24] gt0_rxcdrhold — GT0 RXCDRHOLD (See UG482, Table 4-11)
    [22:20] gt1_rxrate — GT1 RXRATE (See UG482, Table 4-11)
    [18:16] gt0_rxrate — GT0 RXRATE (See UG482, Table 4-11)
    [13] gt1_rxpolarity — GT1 RXPOLARITY (See UG482, Table 4-22)
    [12] gt0_rxpolarity — GT0 RXPOLARITY (See UG482, Table 4-22)
    [10:8] gt1_loopback — GT1 LOOPBACK (See UG482, Table 2-27)
    [6:4] gt0_loopback — GT0 LOOPBACK (See UG482, Table 2-27)
    [3] gt1_txpolarity — GT1 TXPOLARITY (See UG482, Table 3-22)
    [2] gt0_txpolarity — GT0 TXPOLARITY (See UG482, Table 3-22)
    [1] gt1_txinhibit — GT1 TXINHIBIT (See UG482, Table 3-28)
    [0] gt0_txinhibit — GT0 TXINHIBIT (See UG482, Table 3-28)
  0x28 stats0 group — All the statistic registers and their configuration.
    0x00 rd2clr_config — Configures if the stats register read by s/w clears the read register. A 1 in any bit configures the h/w to clear the corresponding stats register after a s/w read of that stats register.
      [4] missing_start, [3] gt1_not_in_table, [2] gt1_disp_err, [1] gt0_not_in_table, [0] gt0_disp_err
    0x04 gt0_disp_err ro — GT0 Disparity Error Count
      [31:0] gt0_disp_err — GT0 RXDISPERR Count (See UG482, Table 4-27)
    0x08 gt0_not_in_table ro — GT0 Not In Table Count
      [31:0] gt0_not_in_table — GT0 RXNOTINTABLE Count (See UG482, Table 4-27)
    0x0C gt1_disp_err ro — GT1 Disparity Error Count
      [31:0] gt1_disp_err — GT1 RXDISPERR Count (See UG482, Table 4-27)
    0x10 gt1_not_in_table ro — GT1 Not In Table Count
      [31:0] gt1_not_in_table — GT1 RXNOTINTABLE Count (See UG482, Table 4-27)
    0x14 missing_start ro — Missing Start Control Character Detected
      [31:0] missing_start — Detected an XGMII Idle instead of an XGMII Start control character
0x1A4 sl_5g group — Single Lane 5G register group
  0x00 gt_rst_ctrl reset 0x11 — GTP Reset Control register
    [10] rxbufreset — RXBUFRESET (Active-High) (See UG482, Table 2-18)
    [9] rxlpmreset — RXLPMRESET (Active-High) (See UG482, Table 2-18)
    [8] eyescanreset — EYESCANRESET (Active-High) (See UG482, Table 2-18)
    [7] rxpmareset — RXPMARESET (Active-High) (See UG482, Table 2-18)
    [6] rxpcsreset — RXPCSRESET (Active-High) (See UG482, Table 2-18)
    [5] dont_reset_on_data_error — Do not automatically reset the RX_STARTUP_FSM of the GTP when DATA_VALID input de-asserts.
    [4] soft_reset_rx — Soft Reset of RX path of the GTP (Active-High) 1'b0 - GTP RX Reset FSM is out of reset 1'b1 - GTP RX Reset FSM is in reset Note: To reset write a 1 followed by a 0
    [2] txpmareset — TXPMARESET (Active-High) (See UG482, Table 2-14)
    [1] txpcsreset — TXPCSRESET (Active-High) (See UG482, Table 2-14)
    [0] soft_reset_tx — Soft Reset of TX path of the GTP (Active-High) 1'b0 - GTP X Reset FSM is out of reset 1'b1 - GTP TX Reset FSM is in reset Note: To reset write a 1 followed by a 0
  0x04 gt_tx_ctrl reset 0x43 — GTP TX Control
    [27] txprbsforceerr — TXPRBSFORCEERR (Active-High) (See UG482, Table 3-20)
    [26:24] txprbssel — TXPRBSSEL (See UG482, Table 3-20)
    [20:16] txpostcursor — TXPOSTCURSOR (See UG482, Table 3-28)
    [12:8] txprecursor — TXPRECURSOR (See UG482, Table 3-28)
    [7:4] txdiffctrl — TXDIFFCTRL (See UG482, Table 3-28)
    [3] txinhibit — TXINHIBIT (See UG482, Table 3-28)
    [2] txpolarity — TXPOLARITY (See UG482, Table 3-22)
    [1:0] txpd — TXPD (See UG482, Table 3-30)
  0x08 gt_rx_ctrl reset 0x3 — GTP RX Control
    [11] rxprbscntreset — RXPRBSCNTRESET (Active-High) (See UG482, Table 4-23)
    [10:8] rxprbssel — RXPRBSSEL (See UG482, Table 4-23)
    [7] rxlpmlfhold — RXLPMLFHOLD (See UG482, Table 4-9)
    [6] rxlpmhfovrden — RXLPMHFOVRDEN (See UG482, Table 4-9)
    [5] rxlpmhfhold — RXLPMHFHOLD (See UG482, Table 4-9)
    [4] rxcdrhold — RXCDRHOLD (See UG482, Table 4-11)
    [3] data_valid_en — DATA_VALID input to the GT RX_STARTUP_FSM is: 1'b0 : always 1 1'b1 : hardware defined (generally the NOT of the OR of all 8B/10B decode errors)
    [2] rxpolarity — RXPOLARITY (See UG482, Table 4-22)
    [1:0] rxpd — RXPD (See UG482, Table 3-30)
  0x0C gt_misc_ctrl — GTP Miscellaneous Control
    [2:0] loopback — LOOPBACK (See UG482, Table 2-27)
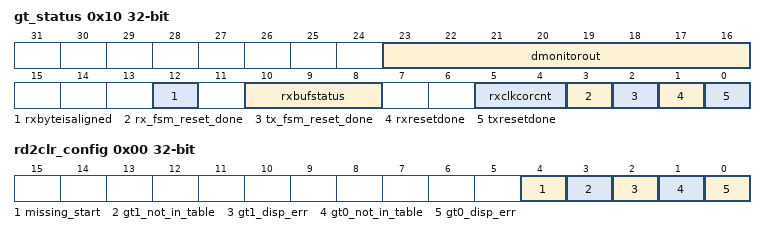
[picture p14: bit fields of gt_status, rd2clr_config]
  0x10 gt_status ro — GTP Status register
    [23:16] dmonitorout — DMONITOROUT[7:0] (See UG482, Table 2-31)
    [12] rxbyteisaligned — RXBYTEISALIGNED (See UG482, Table 4-25)
    [10:8] rxbufstatus — RXBUFSTATUS (See UG482, Table 4-33)
    [5:4] rxclkcorcnt — RXCLKCORCNT (See UG482, Table 4-36)
    [3] rx_fsm_reset_done — RX FSM Reset Done (Active-High)
    [2] tx_fsm_reset_done — TX FSM Reset Done (Active-High)
    [1] rxresetdone — RXRESETDONE (Active-High) (See UG482, Table 2-18)
    [0] txresetdone — TXRESETDONE (Active-High) (See UG482, Table 2-14)
  0x14 stats0 group — All the statistic registers and their configuration.
    0x00 rd2clr_config — Configures if the stats register read by s/w clears the read register. A 1 in any bit configures the h/w to clear the corresponding stats register after a s/w read of that stats register.
      [2] gt_rxbyterealign, [1] gt_not_in_table, [0] gt_disp_err
    0x04 gt_disp_err ro — GT Disparity Error Count
      [31:0] gt_disp_err — GT RXDISPERR Count (See UG482, Table 4-27)
    0x08 gt_not_in_table ro — GT Not In Table Count
      [31:0] gt_not_in_table — GT RXNOTINTABLE Count (See UG482, Table 4-27)
    0x0C gt_rxbyterealign ro — GT RX Byte Realign Count
      [31:0] gt_rxbyterealign — GT RXBYTEREALIGN Count (See UG482, Table 4-25)
